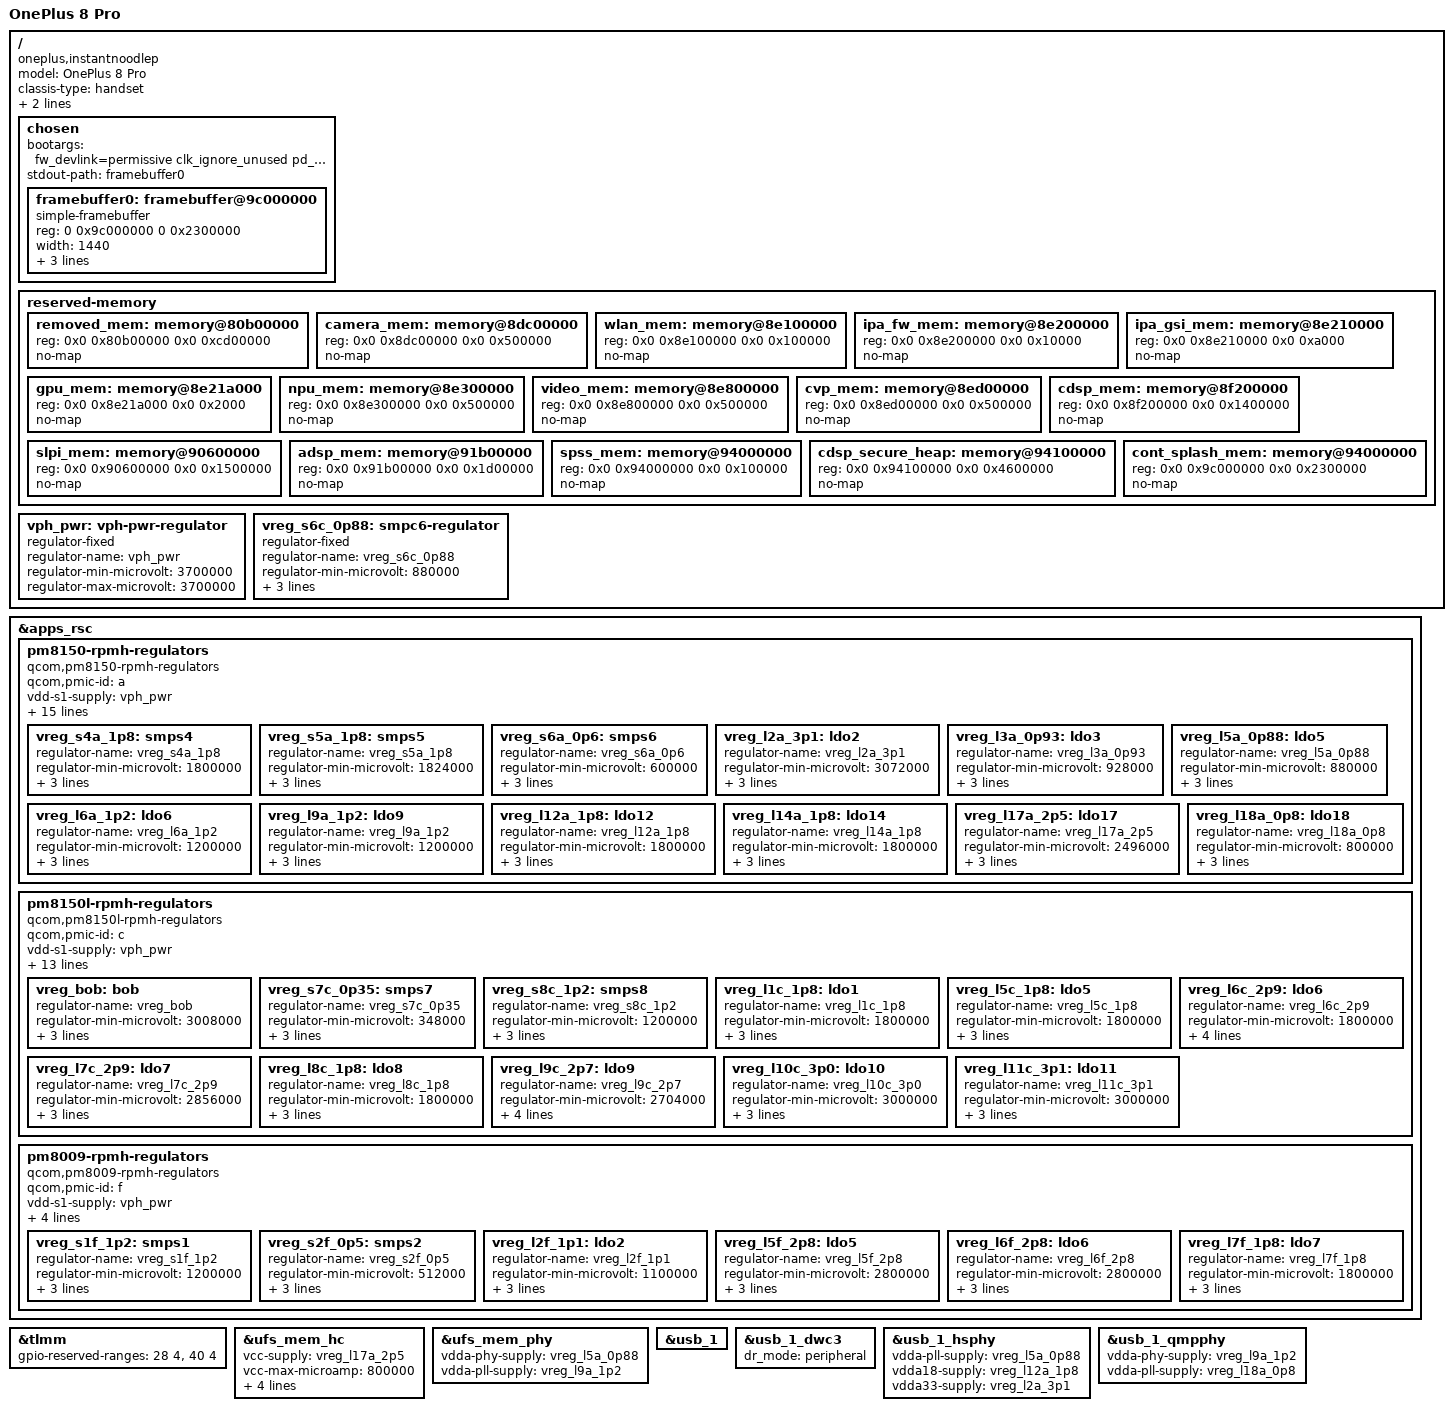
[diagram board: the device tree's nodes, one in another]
// SPDX-License-Identifier: GPL-2.0
/*
 * Copyright (c) 2022, The Linux Foundation. All rights reserved.
 */

/dts-v1/;

#include <dt-bindings/gpio/gpio.h>
#include <dt-bindings/regulator/qcom,rpmh-regulator.h>
#include "sm8250.dtsi"
#include "pm8150.dtsi"
#include "pm8150b.dtsi"
#include "pm8150l.dtsi"
#include "pm8009.dtsi"

/*
 * Delete following upstream (sm8250.dtsi) reserved
 * memory mappings which are different in this device.
 */
/delete-node/ &removed_mem;
/delete-node/ &camera_mem;
/delete-node/ &wlan_mem;
/delete-node/ &ipa_fw_mem;
/delete-node/ &ipa_gsi_mem;
/delete-node/ &gpu_mem;
/delete-node/ &npu_mem;
/delete-node/ &video_mem;
/delete-node/ &cvp_mem;
/delete-node/ &cdsp_mem;
/delete-node/ &slpi_mem;
/delete-node/ &adsp_mem;
/delete-node/ &spss_mem;
/delete-node/ &cdsp_secure_heap;

/ {
	model = "OnePlus 8 Pro";
	compatible = "oneplus,instantnoodlep", "qcom,sm8250";
	classis-type = "handset";

	qcom,msm-id = <0x164 0x20001>;
	qcom,board-id = <0x10008 0>;

	chosen {
		#address-cells = <2>;
		#size-cells = <2>;
		ranges;

		bootargs = "fw_devlink=permissive clk_ignore_unused pd_ignore_unused";
		stdout-path = "framebuffer0";

		framebuffer0: framebuffer@9c000000 {
			compatible = "simple-framebuffer";
			reg = <0 0x9c000000 0 0x2300000>;
			width = <1440>;
			height = <3168>;
			stride = <(1440 * 3)>;
			format = "a8r8g8b8";
		};
	};

	reserved-memory {
		removed_mem: memory@80b00000 {
			reg = <0x0 0x80b00000 0x0 0xcd00000>;
			no-map;
		};

		camera_mem: memory@8dc00000 {
			reg = <0x0 0x8dc00000 0x0 0x500000>;
			no-map;
		};

		wlan_mem: memory@8e100000 {
			reg = <0x0 0x8e100000 0x0 0x100000>;
			no-map;
		};

		ipa_fw_mem: memory@8e200000 {
			reg = <0x0 0x8e200000 0x0 0x10000>;
			no-map;
		};

		ipa_gsi_mem: memory@8e210000 {
			reg = <0x0 0x8e210000 0x0 0xa000>;
			no-map;
		};

		gpu_mem: memory@8e21a000 {
			reg = <0x0 0x8e21a000 0x0 0x2000>;
			no-map;
		};

		npu_mem: memory@8e300000 {
			reg = <0x0 0x8e300000 0x0 0x500000>;
			no-map;
		};

		video_mem: memory@8e800000 {
			reg = <0x0 0x8e800000 0x0 0x500000>;
			no-map;
		};

		cvp_mem: memory@8ed00000 {
			reg = <0x0 0x8ed00000 0x0 0x500000>;
			no-map;
		};

		cdsp_mem: memory@8f200000 {
			reg = <0x0 0x8f200000 0x0 0x1400000>;
			no-map;
		};

		slpi_mem: memory@90600000 {
			reg = <0x0 0x90600000 0x0 0x1500000>;
			no-map;
		};

		adsp_mem: memory@91b00000 {
			reg = <0x0 0x91b00000 0x0 0x1d00000>;
			no-map;
		};

		spss_mem: memory@94000000 {
			reg = <0x0 0x94000000 0x0 0x100000>;
			no-map;
		};

		cdsp_secure_heap: memory@94100000 {
			reg = <0x0 0x94100000 0x0 0x4600000>;
			no-map;
		};

		cont_splash_mem: memory@94000000 {
			reg = <0x0 0x9c000000 0x0 0x2300000>;
			no-map;
		};
	};

	vph_pwr: vph-pwr-regulator {
		compatible = "regulator-fixed";
		regulator-name = "vph_pwr";
		regulator-min-microvolt = <3700000>;
		regulator-max-microvolt = <3700000>;
	};

	/* S6c is really ebi.lvl but it's there for supply map completeness sake. */
	vreg_s6c_0p88: smpc6-regulator {
		compatible = "regulator-fixed";
		regulator-name = "vreg_s6c_0p88";

		regulator-min-microvolt = <880000>;
		regulator-max-microvolt = <880000>;
		regulator-always-on;
		vin-supply = <&vph_pwr>;
	};
};

&apps_rsc {
    pm8150-rpmh-regulators {
        compatible = "qcom,pm8150-rpmh-regulators";
        qcom,pmic-id = "a";

		vdd-s1-supply = <&vph_pwr>;
		vdd-s2-supply = <&vph_pwr>;
		vdd-s3-supply = <&vph_pwr>;
		vdd-s4-supply = <&vph_pwr>;
		vdd-s5-supply = <&vph_pwr>;
		vdd-s6-supply = <&vph_pwr>;
		vdd-s7-supply = <&vph_pwr>;
		vdd-s8-supply = <&vph_pwr>;
		vdd-s9-supply = <&vph_pwr>;
		vdd-s10-supply = <&vph_pwr>;
		vdd-l1-l8-l11-supply = <&vreg_s6c_0p88>;
		vdd-l2-l10-supply = <&vreg_bob>;
		vdd-l3-l4-l5-l18-supply = <&vreg_s6a_0p6>;
		vdd-l6-l9-supply = <&vreg_s8c_1p2>;
		vdd-l7-l12-l14-l15-supply = <&vreg_s5a_1p8>;
		vdd-l13-l16-l17-supply = <&vreg_bob>;

		/* (S1+S2+S3) - cx.lvl (ARC) */

		vreg_s4a_1p8: smps4 {
			regulator-name = "vreg_s4a_1p8";
			regulator-min-microvolt = <1800000>;
			regulator-max-microvolt = <1920000>;
			regulator-initial-mode = <RPMH_REGULATOR_MODE_HPM>;
		};

		vreg_s5a_1p8: smps5 {
			regulator-name = "vreg_s5a_1p8";
			regulator-min-microvolt = <1824000>;
			regulator-max-microvolt = <2040000>;
			regulator-initial-mode = <RPMH_REGULATOR_MODE_HPM>;
		};

		vreg_s6a_0p6: smps6 {
			regulator-name = "vreg_s6a_0p6";
			regulator-min-microvolt = <600000>;
			regulator-max-microvolt = <1128000>;
			regulator-initial-mode = <RPMH_REGULATOR_MODE_HPM>;
		};

		vreg_l2a_3p1: ldo2 {
			regulator-name = "vreg_l2a_3p1";
			regulator-min-microvolt = <3072000>;
			regulator-max-microvolt = <3072000>;
			regulator-initial-mode = <RPMH_REGULATOR_MODE_HPM>;
		};

		vreg_l3a_0p93: ldo3 {
			regulator-name = "vreg_l3a_0p93";
			regulator-min-microvolt = <928000>;
			regulator-max-microvolt = <932000>;
			regulator-initial-mode = <RPMH_REGULATOR_MODE_HPM>;
		};

		/* L4 - lmx.lvl (ARC) */

		vreg_l5a_0p88: ldo5 {
			regulator-name = "vreg_l5a_0p88";
			regulator-min-microvolt = <880000>;
			regulator-max-microvolt = <880000>;
			regulator-initial-mode = <RPMH_REGULATOR_MODE_HPM>;
		};

		vreg_l6a_1p2: ldo6 {
			regulator-name = "vreg_l6a_1p2";
			regulator-min-microvolt = <1200000>;
			regulator-max-microvolt = <1200000>;
			regulator-initial-mode = <RPMH_REGULATOR_MODE_HPM>;
		};

		/* L7 is unused. */
		/*vreg_l7a_1p7: ldo7 {
			regulator-name = "vreg_l7a_1p7";
			regulator-min-microvolt = <1704000>;
			regulator-max-microvolt = <1800000>;
			regulator-initial-mode = <RPMH_REGULATOR_MODE_HPM>;
		};*/

		vreg_l9a_1p2: ldo9 {
			regulator-name = "vreg_l9a_1p2";
			regulator-min-microvolt = <1200000>;
			regulator-max-microvolt = <1200000>;
			regulator-initial-mode = <RPMH_REGULATOR_MODE_HPM>;
		};

		/* L10 is unused, L11 - lcx.lvl (ARC) */
		/*vreg_l10a_1p8: ldo10 {
			regulator-name = "vreg_l10a_1p8";
			regulator-min-microvolt = <1800000>;
			regulator-max-microvolt = <2960000>;
			regulator-initial-mode = <RPMH_REGULATOR_MODE_HPM>;
		};*/

		vreg_l12a_1p8: ldo12 {
			regulator-name = "vreg_l12a_1p8";
			regulator-min-microvolt = <1800000>;
			regulator-max-microvolt = <1800000>;
			regulator-initial-mode = <RPMH_REGULATOR_MODE_HPM>;
		};

		/* L13 is unused. */
		/*vreg_l13a_3p0: ldo13 {
			regulator-name = "vreg_l13a_3p0";
			regulator-min-microvolt = <3008000>;
			regulator-max-microvolt = <3008000>;
			regulator-initial-mode = <RPMH_REGULATOR_MODE_HPM>;
		};*/

		vreg_l14a_1p8: ldo14 {
			regulator-name = "vreg_l14a_1p8";
			regulator-min-microvolt = <1800000>;
			regulator-max-microvolt = <1880000>;
			regulator-initial-mode = <RPMH_REGULATOR_MODE_HPM>;
		};

		/* L15 & L16 are unused. */
		/*vreg_l15a_1p8: ldo15 {
			regulator-name = "vreg_l15a_1p8";
			regulator-min-microvolt = <1800000>;
			regulator-max-microvolt = <1800000>;
			regulator-initial-mode = <RPMH_REGULATOR_MODE_HPM>;
		};

		vreg_l16a_3p0: ldo16 {
			regulator-name = "vreg_l16a_3p0";
			regulator-min-microvolt = <3024000>;
			regulator-max-microvolt = <3304000>;
			regulator-initial-mode = <RPMH_REGULATOR_MODE_HPM>;
		};*/

		vreg_l17a_2p5: ldo17 {
			regulator-name = "vreg_l17a_2p5";
			regulator-min-microvolt = <2496000>;
			regulator-max-microvolt = <3008000>;
			regulator-initial-mode = <RPMH_REGULATOR_MODE_HPM>;
		};

		vreg_l18a_0p8: ldo18 {
			regulator-name = "vreg_l18a_0p8";
			regulator-min-microvolt = <800000>;
			regulator-max-microvolt = <920000>;
			regulator-initial-mode = <RPMH_REGULATOR_MODE_HPM>;
		};
	};

	/*
	 * Remaining regulators that are not yet supported:
	 * OLEDB: 4925000-8100000
	 * ab: 4600000-6100000
	 * ibb: 800000-5400000
	 */

	pm8150l-rpmh-regulators {
		compatible = "qcom,pm8150l-rpmh-regulators";
		qcom,pmic-id = "c";

		vdd-s1-supply = <&vph_pwr>;
		vdd-s2-supply = <&vph_pwr>;
		vdd-s3-supply = <&vph_pwr>;
		vdd-s4-supply = <&vph_pwr>;
		vdd-s5-supply = <&vph_pwr>;
		vdd-s6-supply = <&vph_pwr>;
		vdd-s7-supply = <&vph_pwr>;
		vdd-s8-supply = <&vph_pwr>;
		vdd-l1-l8-supply = <&vreg_s4a_1p8>;
		vdd-l2-l3-supply = <&vreg_s8c_1p2>;
		vdd-l4-l5-l6-supply = <&vreg_bob>;
		vdd-l7-l11-supply = <&vreg_bob>;
		vdd-l9-l10-supply = <&vreg_bob>;
		vdd-bob-supply = <&vph_pwr>;

		vreg_bob: bob {
			regulator-name = "vreg_bob";
			regulator-min-microvolt = <3008000>;
			regulator-max-microvolt = <3960000>;
			regulator-initial-mode = <RPMH_REGULATOR_MODE_AUTO>;
		};

		/*
		 * S1-S6 are ARCs:
		 * (S1+S2) - gfx.lvl,
		 * S3 - mx.lvl,
		 * (S4+S5) - mmcx.lvl,
		 * S6 - ebi.lvl
		 */

		vreg_s7c_0p35: smps7 {
			regulator-name = "vreg_s7c_0p35";
			regulator-min-microvolt = <348000>;
			regulator-max-microvolt = <1000000>;
			regulator-initial-mode = <RPMH_REGULATOR_MODE_HPM>;
		};

		vreg_s8c_1p2: smps8 {
			regulator-name = "vreg_s8c_1p2";
			regulator-min-microvolt = <1200000>;
			regulator-max-microvolt = <1400000>;
			regulator-initial-mode = <RPMH_REGULATOR_MODE_HPM>;
		};

		vreg_l1c_1p8: ldo1 {
			regulator-name = "vreg_l1c_1p8";
			regulator-min-microvolt = <1800000>;
			regulator-max-microvolt = <1800000>;
			regulator-initial-mode = <RPMH_REGULATOR_MODE_HPM>;
		};

		/* L2-4 are unused. */
		/*vreg_l2c_1p3: ldo2 {
			regulator-name = "vreg_l2c_1p3";
			regulator-min-microvolt = <1300000>;
			regulator-max-microvolt = <1300000>;
			regulator-initial-mode = <RPMH_REGULATOR_MODE_HPM>;
		};

		vreg_l3c_0p8: ldo3 {
			regulator-name = "vreg_l3c_0p8";
			regulator-min-microvolt = <800000>;
			regulator-max-microvolt = <1200000>;
			regulator-initial-mode = <RPMH_REGULATOR_MODE_HPM>;
		};

		vreg_l4c_1p8: ldo4 {
			regulator-name = "vreg_l4c_1p8";
			regulator-min-microvolt = <1800000>;
			regulator-max-microvolt = <2800000>;
			regulator-initial-mode = <RPMH_REGULATOR_MODE_HPM>;
		};*/

		vreg_l5c_1p8: ldo5 {
			regulator-name = "vreg_l5c_1p8";
			regulator-min-microvolt = <1800000>;
			regulator-max-microvolt = <2800000>;
			regulator-initial-mode = <RPMH_REGULATOR_MODE_HPM>;
		};

		vreg_l6c_2p9: ldo6 {
			regulator-name = "vreg_l6c_2p9";
			regulator-min-microvolt = <1800000>;
			regulator-max-microvolt = <2960000>;
			regulator-initial-mode = <RPMH_REGULATOR_MODE_HPM>;
			regulator-allow-set-load;
		};

		vreg_l7c_2p9: ldo7 {
			regulator-name = "vreg_l7c_2p9";
			regulator-min-microvolt = <2856000>;
			regulator-max-microvolt = <3104000>;
			regulator-initial-mode = <RPMH_REGULATOR_MODE_HPM>;
		};

		vreg_l8c_1p8: ldo8 {
			regulator-name = "vreg_l8c_1p8";
			regulator-min-microvolt = <1800000>;
			regulator-max-microvolt = <1800000>;
			regulator-initial-mode = <RPMH_REGULATOR_MODE_HPM>;
		};

		vreg_l9c_2p7: ldo9 {
			regulator-name = "vreg_l9c_2p7";
			regulator-min-microvolt = <2704000>;
			regulator-max-microvolt = <2960000>;
			regulator-initial-mode = <RPMH_REGULATOR_MODE_HPM>;
			regulator-allow-set-load;
		};

		vreg_l10c_3p0: ldo10 {
			regulator-name = "vreg_l10c_3p0";
			regulator-min-microvolt = <3000000>;
			regulator-max-microvolt = <3312000>;
			regulator-initial-mode = <RPMH_REGULATOR_MODE_HPM>;
		};

		vreg_l11c_3p1: ldo11 {
			regulator-name = "vreg_l11c_3p1";
			regulator-min-microvolt = <3000000>;
			regulator-max-microvolt = <3000000>;
			regulator-initial-mode = <RPMH_REGULATOR_MODE_HPM>;
		};
	};

	pm8009-rpmh-regulators {
		compatible = "qcom,pm8009-rpmh-regulators";
		qcom,pmic-id = "f";

		vdd-s1-supply = <&vph_pwr>;
		vdd-s2-supply = <&vreg_bob>;
		vdd-l2-supply = <&vreg_s8c_1p2>;
		vdd-l5-l6-supply = <&vreg_bob>;
		vdd-l7-supply = <&vreg_s4a_1p8>;

		vreg_s1f_1p2: smps1 {
			regulator-name = "vreg_s1f_1p2";
			regulator-min-microvolt = <1200000>;
			regulator-max-microvolt = <1200000>;
			regulator-initial-mode = <RPMH_REGULATOR_MODE_HPM>;
		};

		vreg_s2f_0p5: smps2 {
			regulator-name = "vreg_s2f_0p5";
			regulator-min-microvolt = <512000>;
			regulator-max-microvolt = <1100000>;
			regulator-initial-mode = <RPMH_REGULATOR_MODE_HPM>;
		};

		/* L1 is unused. */
		/*vreg_l1f_1p1: ldo1 {
			regulator-name = "vreg_l1f_1p1";
			regulator-min-microvolt = <1104000>;
			regulator-max-microvolt = <1104000>;
			regulator-initial-mode = <RPMH_REGULATOR_MODE_HPM>;
		};*/

		vreg_l2f_1p1: ldo2 {
			regulator-name = "vreg_l2f_1p1";
			regulator-min-microvolt = <1100000>;
			regulator-max-microvolt = <1100000>;
			regulator-initial-mode = <RPMH_REGULATOR_MODE_HPM>;
		};

		/* L3 & L4 are unused. */
		/*vreg_l3f_1p05: ldo3 {
			regulator-name = "vreg_l3f_1p05";
			regulator-min-microvolt = <1056000>;
			regulator-max-microvolt = <1056000>;
			regulator-initial-mode = <RPMH_REGULATOR_MODE_HPM>;
		};
		
		vreg_l4f_1p05: ldo4 {
			regulator-name = "vreg_l4f_1p05";
			regulator-min-microvolt = <1056000>;
			regulator-max-microvolt = <1056000>;
			regulator-initial-mode = <RPMH_REGULATOR_MODE_HPM>;
		};*/

		vreg_l5f_2p8: ldo5 {
			regulator-name = "vreg_l5f_2p8";
			regulator-min-microvolt = <2800000>;
			regulator-max-microvolt = <3000000>;
			regulator-initial-mode = <RPMH_REGULATOR_MODE_HPM>;
		};

		vreg_l6f_2p8: ldo6 {
			regulator-name = "vreg_l6f_2p8";
			regulator-min-microvolt = <2800000>;
			regulator-max-microvolt = <3000000>;
			regulator-initial-mode = <RPMH_REGULATOR_MODE_HPM>;
		};

		vreg_l7f_1p8: ldo7 {
			regulator-name = "vreg_l7f_1p8";
			regulator-min-microvolt = <1800000>;
			regulator-max-microvolt = <1800000>;
			regulator-initial-mode = <RPMH_REGULATOR_MODE_HPM>;
		};
	};
};

&tlmm {
	gpio-reserved-ranges = <28 4>, <40 4>;
};

&ufs_mem_hc {
	status = "okay";

	vcc-supply = <&vreg_l17a_2p5>;
	vcc-max-microamp = <800000>;
	vccq-supply = <&vreg_l6a_1p2>;
	vccq-max-microamp = <800000>;
	vccq2-supply = <&vreg_s4a_1p8>;
	vccq2-max-microamp = <800000>;
};

&ufs_mem_phy {
	status = "okay";

	vdda-phy-supply = <&vreg_l5a_0p88>;
	vdda-pll-supply = <&vreg_l9a_1p2>;
};

&usb_1 {
	status = "okay";
};

&usb_1_dwc3 {
	dr_mode = "peripheral";
};

&usb_1_hsphy {
	status = "okay";

	vdda-pll-supply = <&vreg_l5a_0p88>;
	vdda18-supply = <&vreg_l12a_1p8>;
	vdda33-supply = <&vreg_l2a_3p1>;
};

&usb_1_qmpphy {
	status = "okay";

	vdda-phy-supply = <&vreg_l9a_1p2>;
	vdda-pll-supply = <&vreg_l18a_0p8>;
};
